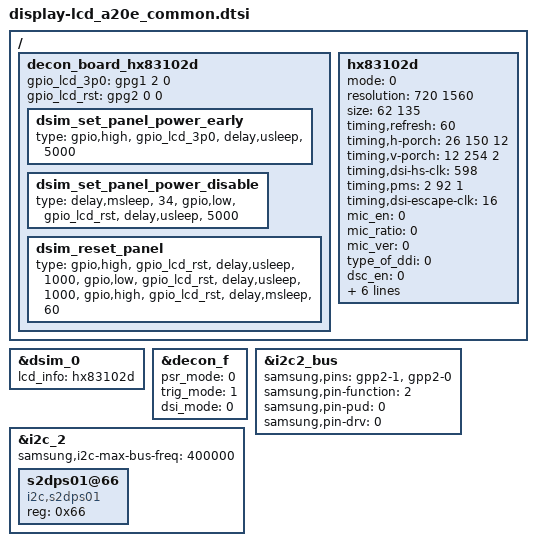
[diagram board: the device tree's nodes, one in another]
/*
 * SAMSUNG LCD Panel Device Tree Source
 *
 * Copyright (c) Samsung Electronics Co., Ltd.
 *		http://www.samsung.com
 *
 * This program is free software; you can redistribute it and/or modify
 * it under the terms of the GNU General Public License version 2 as
 * published by the Free Software Foundation.
 */

/ {
	fragment@lcd {
		target-path = "/";
		__overlay__ {
			decon_board_hx83102d: decon_board_hx83102d {
				gpio_lcd_3p0 = <&gpg1 2 0>;
				gpio_lcd_rst = <&gpg2 0 0>;

				dsim_set_panel_power_early {
					type =
					"gpio,high",	"gpio_lcd_3p0",
					"delay,usleep",	"5000";
				};
				dsim_set_panel_power_disable {
					type =
					"delay,msleep",	"34",
					"gpio,low",	"gpio_lcd_rst",
					"delay,usleep",	"5000";
				};
				dsim_reset_panel {
					type =
					"gpio,high",	"gpio_lcd_rst",
					"delay,usleep",	"1000",
					"gpio,low",	"gpio_lcd_rst",
					"delay,usleep",	"1000",
					"gpio,high",	"gpio_lcd_rst",
					"delay,msleep",	"60";
				};
			};

			hx83102d: hx83102d {
				mode = <0>; /* 0: video mode, 1: DP command mode, 2: MIPI command mode */
				resolution = <720 1560>;
				size = <62 135>;	/* 62.1 x 134.55 */
				timing,refresh = <60>;
				/* dsim H porch : HBP, HFP, HSA */
				timing,h-porch = <26 150 12>;
				/* dsim V porch : VBP, VFP, VSA */
				timing,v-porch = <12 254 2>;
				timing,dsi-hs-clk = <598>;
				timing,pms = <2 92 1>;
				timing,dsi-escape-clk = <16>;
				mic_en = <0>;		/* 0: Disable, 1: Enable */
				mic_ratio = <0>;	/* 0: 1/2 mic, 1: 1/3 mic */
				mic_ver = <0>;		/* 0: mic v1.1, 1: v1.2, 2: v2.0 */
				type_of_ddi = <0>;	/* 0: Samsung Mobile, 1: MAGNA, 2: Normal(Etc) */
				dsc_en = <0>;		/* 0: Disable, 1: Enable */
				dsc_cnt = <0>;		/* used DSC count */
				dsc_slice_num = <0>;	/* count of dsc slice */
				data_lane = <4>;	/* number of using data lane */
				vt_compensation = <455>;	/* for difference between wordclk and vclk at video mode */
				eotp_disabled = <1>;	/* 0:EOTP Enable, 1: EOTP Disable */
				decon_board = <&decon_board_hx83102d>;
			};
		};
	};
};

&dsim_0 {
	lcd_info = <&hx83102d>;
};

&decon_f {
	psr_mode = <0>;		/* 0: video mode, 1: DP command mode, 2: MIPI command mode */
	trig_mode = <1>;	/* 0: hw trigger, 1: sw trigger */
	dsi_mode = <0>;		/* 0: single dsi, 1: dual dsi */
};

/* pinctrl_3: pinctrl@139B0000 */
&i2c2_bus {
	samsung,pins = "gpp2-1", "gpp2-0";
	samsung,pin-function = <2>;
	samsung,pin-pud = <0>;
	samsung,pin-drv = <0>;
};

/* i2c_2: i2c@13850000 */
&i2c_2 {
	status = "okay";
	samsung,i2c-max-bus-freq = <400000>;

	s2dps01@66 {
		compatible = "i2c,s2dps01";
		reg = <0x66>;
	};
};

